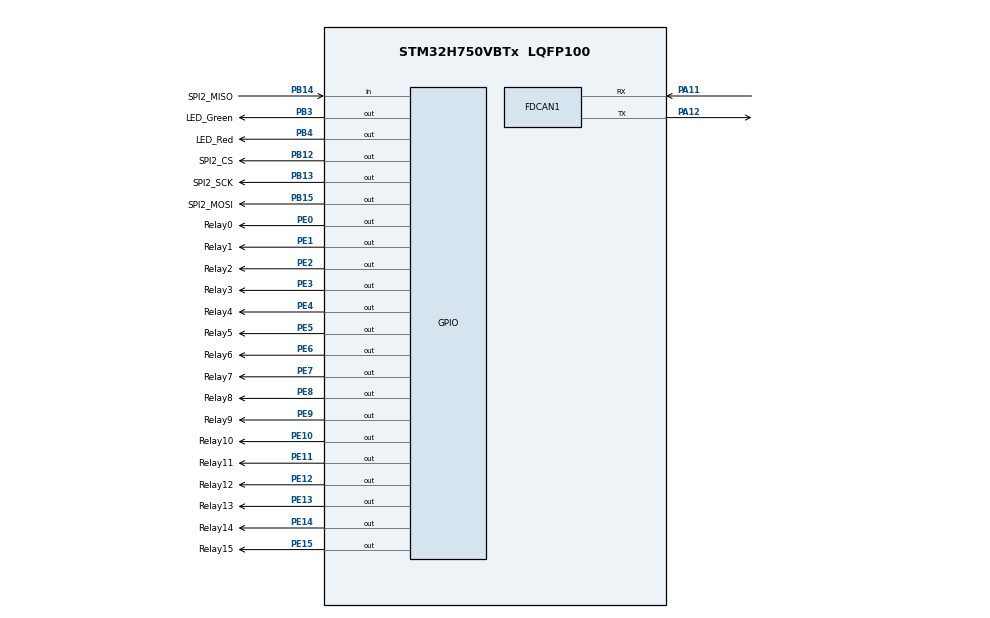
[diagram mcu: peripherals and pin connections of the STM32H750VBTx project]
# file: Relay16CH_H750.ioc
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CORTEX_M7.CPU_DCache=Enabled
CORTEX_M7.CPU_ICache=Enabled
FDCAN1.AutoRetransmission=ENABLE
FDCAN1.CalculateBaudRateNominal=500000
FDCAN1.CalculateTimeBitNominal=2000
FDCAN1.CalculateTimeQuantumNominal=100.0
FDCAN1.DataPrescaler=2
FDCAN1.DataTimeSeg1=15
FDCAN1.DataTimeSeg2=4
FDCAN1.ExtFiltersNbr=0
FDCAN1.FrameFormat=FDCAN_FRAME_FD_BRS
FDCAN1.NominalPrescaler=8
FDCAN1.NominalTimeSeg1=15
FDCAN1.NominalTimeSeg2=4
FDCAN1.RxBufferSize=FDCAN_DATA_BYTES_64
FDCAN1.RxFifo0ElmtSize=FDCAN_DATA_BYTES_64
FDCAN1.RxFifo0ElmtsNbr=4
FDCAN1.RxFifo1ElmtSize=FDCAN_DATA_BYTES_64
FDCAN1.StdFiltersNbr=0
FDCAN1.TxElmtSize=FDCAN_DATA_BYTES_64
FDCAN1.TxEventsNbr=0
FDCAN1.TxFifoQueueElmtsNbr=3
Mcu.Family=STM32H7
Mcu.Name=STM32H750VBTx
Mcu.Package=LQFP100
NVIC.FDCAN1_IT0_IRQn=true\:2\:0\:true\:false\:true\:true\:true\:true
NVIC.PriorityGroup=NVIC_PRIORITYGROUP_4
NVIC.TIM1_UP_IRQn=true\:0\:0\:false\:false\:true\:true\:true\:true
PA11.Mode=FDCAN_Activate
PA11.Signal=FDCAN1_RX
PA12.Mode=FDCAN_Activate
PA12.Signal=FDCAN1_TX
PA13\ (JTMS/SWDIO).Mode=Serial_Wire
PA13\ (JTMS/SWDIO).Signal=DEBUG_JTMS-SWDIO
PA14\ (JTCK/SWCLK).Mode=Serial_Wire
PA14\ (JTCK/SWCLK).Signal=DEBUG_JTCK-SWCLK
PB12.GPIO_Label=SPI2_CS
PB12.GPIO_Speed=GPIO_SPEED_FREQ_VERY_HIGH
PB12.Signal=GPIO_Output
PB13.GPIO_Label=SPI2_SCK
PB13.GPIO_Speed=GPIO_SPEED_FREQ_VERY_HIGH
PB13.Signal=GPIO_Output
PB14.GPIO_Label=SPI2_MISO
PB14.Signal=GPIO_Input
PB15.GPIO_Label=SPI2_MOSI
PB15.GPIO_Speed=GPIO_SPEED_FREQ_VERY_HIGH
PB15.Signal=GPIO_Output
PB3\ (JTDO/TRACESWO).GPIO_Label=LED_Green
PB3\ (JTDO/TRACESWO).GPIO_PuPd=GPIO_PULLUP
PB3\ (JTDO/TRACESWO).Signal=GPIO_Output
PB4\ (NJTRST).GPIO_Label=LED_Red
PB4\ (NJTRST).GPIO_PuPd=GPIO_PULLUP
PB4\ (NJTRST).Signal=GPIO_Output
PE0.GPIO_Label=Relay0
PE0.Signal=GPIO_Output
PE1.GPIO_Label=Relay1
PE1.Signal=GPIO_Output
PE10.GPIO_Label=Relay10
PE10.Signal=GPIO_Output
PE11.GPIO_Label=Relay11
PE11.Signal=GPIO_Output
PE12.GPIO_Label=Relay12
PE12.Signal=GPIO_Output
PE13.GPIO_Label=Relay13
PE13.Signal=GPIO_Output
PE14.GPIO_Label=Relay14
PE14.Signal=GPIO_Output
PE15.GPIO_Label=Relay15
PE15.Signal=GPIO_Output
PE2.GPIO_Label=Relay2
PE2.Signal=GPIO_Output
PE3.GPIO_Label=Relay3
PE3.Signal=GPIO_Output
PE4.GPIO_Label=Relay4
PE4.Signal=GPIO_Output
PE5.GPIO_Label=Relay5
PE5.Signal=GPIO_Output
PE6.GPIO_Label=Relay6
PE6.Signal=GPIO_Output
PE7.GPIO_Label=Relay7
PE7.Signal=GPIO_Output
PE8.GPIO_Label=Relay8
PE8.Signal=GPIO_Output
PE9.GPIO_Label=Relay9
PE9.Signal=GPIO_Output
PH0-OSC_IN\ (PH0).Mode=HSE-External-Oscillator
PH0-OSC_IN\ (PH0).Signal=RCC_OSC_IN
PH1-OSC_OUT\ (PH1).Mode=HSE-External-Oscillator
PH1-OSC_OUT\ (PH1).Signal=RCC_OSC_OUT
ProjectManager.HeapSize=0x400
ProjectManager.StackSize=0x800
ProjectManager.TargetToolchain=CMake
RCC.ADCCLockSelection=RCC_ADCCLKSOURCE_PLL2
RCC.ADCFreq_Value=80000000
RCC.APB1Freq_Value=100000000
RCC.APB2Freq_Value=100000000
RCC.APB3Freq_Value=100000000
RCC.APB4Freq_Value=100000000
RCC.CECCLockSelection=RCC_CECCLKSOURCE_LSI
RCC.CKPERSourceSelection=RCC_CLKPSOURCE_HSI
RCC.CSI_VALUE=4000000
RCC.CortexFreq_Value=400000000
RCC.Cortex_Div=SYSTICK_CLKSOURCE_HCLK
RCC.Cortex_DivARG=SystemCoreClock/1000
RCC.D1CPRE=RCC_SYSCLK_DIV1
RCC.D1PPRE=RCC_APB3_DIV2
RCC.D2PPRE1=RCC_APB1_DIV2
RCC.D2PPRE2=RCC_APB2_DIV2
RCC.D3PPRE=RCC_APB4_DIV2
RCC.DFSDMCLockSelection=RCC_DFSDM1CLKSOURCE_D2PCLK1
RCC.DIVM1=2
RCC.DIVM2=2
RCC.DIVM3=32
RCC.DIVN1=200
RCC.DIVN2=40
RCC.DIVN3=129
RCC.DIVP1=2
RCC.DIVP3=2
RCC.DIVQ1=10
RCC.DIVQ2=2
RCC.DIVQ3=2
RCC.DIVR1=10
RCC.DIVR2=2
RCC.DIVR3=2
RCC.DSICLockSelection=RCC_DSICLKSOURCE_PHY
RCC.DSIPHY_Div=8
RCC.DSITX_Div=4
RCC.DSI_PHY_VALUE=12288000
RCC.EXTERNAL_CLOCK_VALUE=12288000
RCC.EnbaleCSS=false
RCC.HCLKFreq_Value=200000000
RCC.HPRE=RCC_HCLK_DIV2
RCC.HSE_VALUE=8000000
RCC.HSIDiv=RCC_PLLSAIDIVR_1
RCC.HSI_VALUE=64000000
RCC.I2C123CLockSelection=RCC_I2C123CLKSOURCE_D2PCLK1
RCC.I2C4CLockSelection=RCC_I2C4CLKSOURCE_D3PCLK1
RCC.LPTIM1CLockSelection=RCC_LPTIM1CLKSOURCE_D2PCLK1
RCC.LPTIM2CLockSelection=RCC_LPTIM2CLKSOURCE_D3PCLK1
RCC.LPTIM345CLockSelection=RCC_LPTIM345CLKSOURCE_D3PCLK1
RCC.LPUART1CLockSelection=RCC_LPUART1CLKSOURCE_D3PCLK1
RCC.LSEState=RCC_LSE_OFF
RCC.LSE_VALUE=32768
RCC.PLL1_VCI_Range-AdvancedSettings=RCC_PLL1VCIRANGE_3
RCC.PLL2FRACN=0
RCC.PLL3FRACN=0
RCC.PLLDSIDev=2
RCC.PLLDSIIDF=DSI_PLL_IN_DIV1
RCC.PLLDSIMult=2
RCC.PLLDSINDIV=20
RCC.PLLDSIODF=DSI_PLL_OUT_DIV1
RCC.PLLFRACN=0
RCC.PLLSourceVirtual=RCC_PLLSOURCE_HSE
RCC.QSPICLockSelection=RCC_QSPICLKSOURCE_D1HCLK
RCC.RC48_VALUE=48000000
RCC.RCC_MCO1Source=RCC_MCO1SOURCE_HSE
RCC.RCC_MCO2Source=RCC_MCO2SOURCE_SYSCLK
RCC.RCC_MCODiv1=RCC_MCODIV_1
RCC.RCC_MCODiv2=RCC_MCODIV_1
RCC.RCC_RTC_Clock_Source_FROM_HSE=RCC_RTCCLKSOURCE_HSE_DIV2
RCC.RNGCLockSelection=RCC_RNGCLKSOURCE_HSI48
RCC.SAI1CLockSelection=RCC_SAI1CLKSOURCE_PLL
RCC.SAI23CLockSelection=RCC_SAI23CLKSOURCE_PLL
RCC.SAI4ACLockSelection=RCC_SAI4ACLKSOURCE_PLL
RCC.SAI4BCLockSelection=RCC_SAI4BCLKSOURCE_PLL
RCC.SPDIFCLockSelection=RCC_SPDIFRXCLKSOURCE_PLL
RCC.SPI123CLockSelection=RCC_SPI123CLKSOURCE_PLL
RCC.SPI6CLockSelection=RCC_SPI6CLKSOURCE_D3PCLK1
RCC.SWPCLockSelection=RCC_SWPMI1CLKSOURCE_D2PCLK1
RCC.SYSCLKFreq_VALUE=400000000
RCC.SYSCLKSource=RCC_SYSCLKSOURCE_PLLCLK
RCC.Spi45ClockSelection=RCC_SPI45CLKSOURCE_PLL2
RCC.USART16CLockSelection=RCC_USART16CLKSOURCE_D2PCLK2
RCC.USART234578CLockSelection=RCC_USART234578CLKSOURCE_D2PCLK1
RCC.USBCLockSelection=RCC_USBCLKSOURCE_PLL
RCC.USBFreq_Value=80000000
TIM1.Period=500-1
TIM1.Prescaler=200-1
VP_CRC_VS_CRC.Mode=CRC_Activate
VP_TIM1_VS_ClockSourceINT.Mode=Internal
board=custom

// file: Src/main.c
/* USER CODE BEGIN Header */
/**
  ******************************************************************************
  * @file           : main.c
  * @brief          : Main program body
  ******************************************************************************
  * @attention
  *
  * Copyright (c) 2024 STMicroelectronics.
  * All rights reserved.
  *
  * This software is licensed under terms that can be found in the LICENSE file
  * in the root directory of this software component.
  * If no LICENSE file comes with this software, it is provided AS-IS.
  *
  ******************************************************************************
  */
/* USER CODE END Header */
#include "main.h"
#include "crc.h"
#include "fdcan.h"
#include "tim.h"
#include "gpio.h"

void SystemClock_Config(void);

int main(void)
{
/* Enable the CPU Cache */

  /* Enable I-Cache---------------------------------------------------------*/
  SCB_EnableICache();

  /* Enable D-Cache---------------------------------------------------------*/
  SCB_EnableDCache();

  /* MCU Configuration--------------------------------------------------------*/

  /* Reset of all peripherals, Initializes the Flash interface and the Systick. */
  HAL_Init();

  /* Configure the system clock */
  SystemClock_Config();

  /* Initialize all configured peripherals */
  MX_GPIO_Init();
  MX_FDCAN1_Init();
  MX_CRC_Init();
  MX_TIM1_Init();
  /* USER CODE BEGIN 2 */
  Relays_Start();
  //HAL_GPIO_WritePin(LED_Green_GPIO_Port, LED_Green_Pin, GPIO_PIN_RESET);
  //HAL_GPIO_WritePin(LED_Red_GPIO_Port, LED_Red_Pin, GPIO_PIN_RESET);
  /* USER CODE END 2 */

  /* Infinite loop */
  /* USER CODE BEGIN WHILE */
  while (1)
  {
	 //HAL_GPIO_TogglePin(LED_Red_GPIO_Port, LED_Red_Pin);

	 //Delay1ms(1000);
    /* USER CODE END WHILE */

  }
}

void SystemClock_Config(void)
{
  RCC_OscInitTypeDef RCC_OscInitStruct = {0};
  RCC_ClkInitTypeDef RCC_ClkInitStruct = {0};

  /** Supply configuration update enable
  */
  HAL_PWREx_ConfigSupply(PWR_LDO_SUPPLY);

  /** Configure the main internal regulator output voltage
  */
  __HAL_PWR_VOLTAGESCALING_CONFIG(PWR_REGULATOR_VOLTAGE_SCALE1);

  while(!__HAL_PWR_GET_FLAG(PWR_FLAG_VOSRDY)) {}

  /** Initializes the RCC Oscillators according to the specified parameters
  * in the RCC_OscInitTypeDef structure.
  */
  RCC_OscInitStruct.OscillatorType = RCC_OSCILLATORTYPE_HSE;
  RCC_OscInitStruct.HSEState = RCC_HSE_ON;
  RCC_OscInitStruct.PLL.PLLState = RCC_PLL_ON;
  RCC_OscInitStruct.PLL.PLLSource = RCC_PLLSOURCE_HSE;
  RCC_OscInitStruct.PLL.PLLM = 2;
  RCC_OscInitStruct.PLL.PLLN = 200;
  RCC_OscInitStruct.PLL.PLLP = 2;
  RCC_OscInitStruct.PLL.PLLQ = 10;
  RCC_OscInitStruct.PLL.PLLR = 10;
  RCC_OscInitStruct.PLL.PLLRGE = RCC_PLL1VCIRANGE_2;
  RCC_OscInitStruct.PLL.PLLVCOSEL = RCC_PLL1VCOWIDE;
  RCC_OscInitStruct.PLL.PLLFRACN = 0;
  if (HAL_RCC_OscConfig(&RCC_OscInitStruct) != HAL_OK)
  {
    Error_Handler();
  }

  /** Initializes the CPU, AHB and APB buses clocks
  */
  RCC_ClkInitStruct.ClockType = RCC_CLOCKTYPE_HCLK|RCC_CLOCKTYPE_SYSCLK
                              |RCC_CLOCKTYPE_PCLK1|RCC_CLOCKTYPE_PCLK2
                              |RCC_CLOCKTYPE_D3PCLK1|RCC_CLOCKTYPE_D1PCLK1;
  RCC_ClkInitStruct.SYSCLKSource = RCC_SYSCLKSOURCE_PLLCLK;
  RCC_ClkInitStruct.SYSCLKDivider = RCC_SYSCLK_DIV1;
  RCC_ClkInitStruct.AHBCLKDivider = RCC_HCLK_DIV2;
  RCC_ClkInitStruct.APB3CLKDivider = RCC_APB3_DIV2;
  RCC_ClkInitStruct.APB1CLKDivider = RCC_APB1_DIV2;
  RCC_ClkInitStruct.APB2CLKDivider = RCC_APB2_DIV2;
  RCC_ClkInitStruct.APB4CLKDivider = RCC_APB4_DIV2;

  if (HAL_RCC_ClockConfig(&RCC_ClkInitStruct, FLASH_LATENCY_2) != HAL_OK)
  {
    Error_Handler();
  }
}

void Error_Handler(void)
{
  /* USER CODE BEGIN Error_Handler_Debug */
  /* User can add his own implementation to report the HAL error return state */
  __disable_irq();
  while (1)
  {
	  //HAL_GPIO_TogglePin(LED_Red_GPIO_Port, LED_Red_Pin);
	  //Delay1ms(1000);
  }
  /* USER CODE END Error_Handler_Debug */
}
